VERSION "8"

NS_ :

BS_:

BU_:Matrix

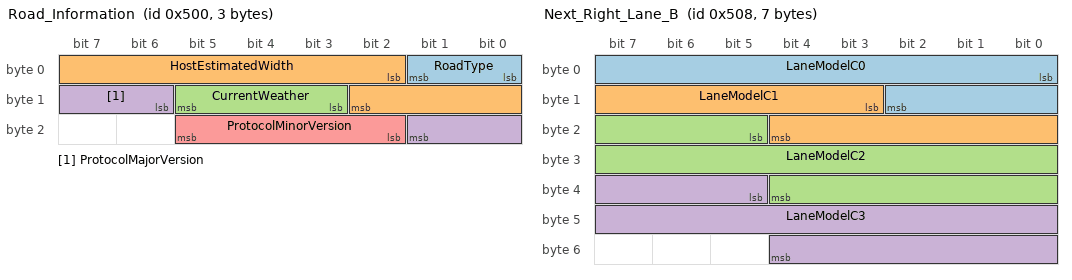
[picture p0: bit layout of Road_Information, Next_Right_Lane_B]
BO_ 1280 Road_Information: 3 Matrix
 SG_ RoadType : 0|2@1+ (1,0) [0|3] "Enum" Matrix
 SG_ HostEstimatedWidth : 2|9@1+ (1,0.01) [0|4] "meter" Matrix
 SG_ CurrentWeather : 11|3@1+ (1,0) [0|7] "Enum" Matrix
 SG_ ProtocolMajorVersion : 14|4@1+ (1,0) [0|15] "NA" Matrix
 SG_ ProtocolMinorVersion : 18|4@1+ (1,0) [0|15] "NA" Matrix

BO_ 1288 Next_Right_Lane_B: 7 Matrix
 SG_ LaneModelC0 : 0|11@1- (0.01,0) [-10|10] "meter" Matrix
 SG_ LaneModelC1 : 11|10@1+ (0.0009765625,-0.357) [-0.357|0.357] "rad" Matrix
 SG_ LaneModelC2 : 21|16@1- (9.77E-007,0) [-0.032|0.032] "1/meter" Matrix
 SG_ LaneModelC3 : 37|16@1- (3.7252902985E-009,0) [-0.000122|0.000122] "1/meter^2" Matrix

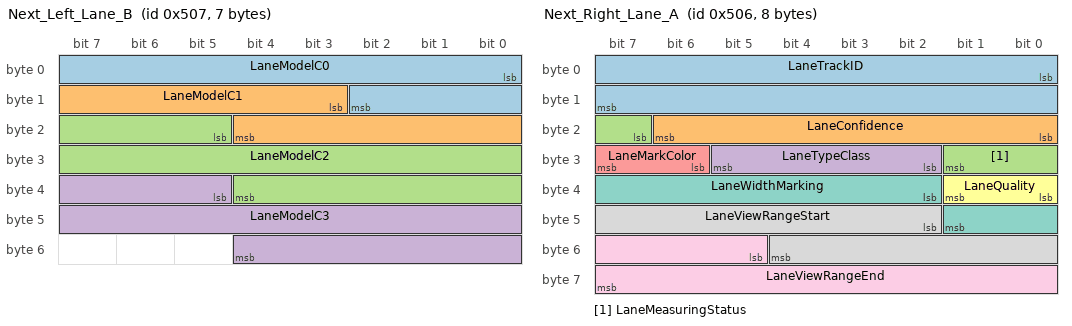
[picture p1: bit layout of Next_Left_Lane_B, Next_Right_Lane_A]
BO_ 1287 Next_Left_Lane_B: 7 Matrix
 SG_ LaneModelC0 : 0|11@1- (0.01,0) [-10|10] "meter" Matrix
 SG_ LaneModelC1 : 11|10@1+ (0.0009765625,-0.357) [-0.357|0.357] "rad" Matrix
 SG_ LaneModelC2 : 21|16@1- (9.77E-007,0) [-0.032|0.032] "1/meter" Matrix
 SG_ LaneModelC3 : 37|16@1- (3.7252902985E-009,0) [-0.000122|0.000122] "1/meter^2" Matrix

BO_ 1286 Next_Right_Lane_A: 8 Matrix
 SG_ LaneTrackID : 0|16@1+ (1,0) [0|65535] "NA" Matrix
 SG_ LaneConfidence : 16|7@1+ (1,0) [0|100] "prob" Matrix
 SG_ LaneMeasuringStatus : 23|3@1+ (1,0) [0|7] "enum" Matrix
 SG_ LaneTypeClass : 26|4@1+ (1,0) [0|15] "Enum" Matrix
 SG_ LaneMarkColor : 30|2@1+ (1,0) [0|3] "Enum" Matrix
 SG_ LaneQuality : 32|2@1+ (1,0) [0|3] "Enum" Matrix
 SG_ LaneWidthMarking : 34|8@1+ (0.01,0) [0|1] "m" Matrix
 SG_ LaneViewRangeStart : 42|11@1+ (0.1,0) [0|200] "meter" Matrix
 SG_ LaneViewRangeEnd : 53|11@1+ (0.1,0) [0|200] "meter" Matrix

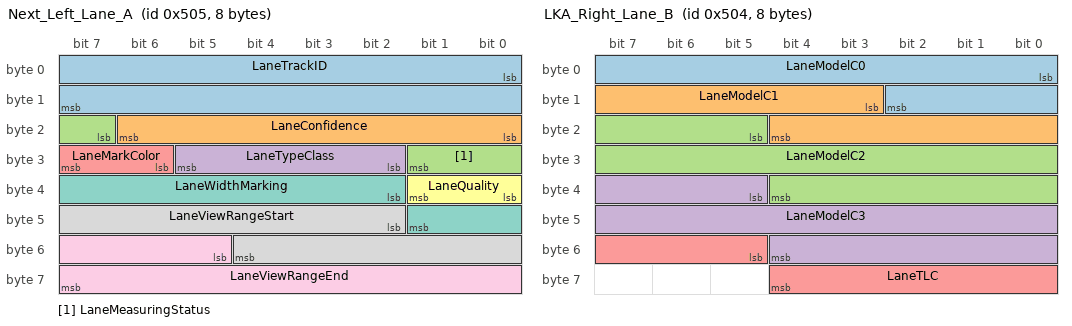
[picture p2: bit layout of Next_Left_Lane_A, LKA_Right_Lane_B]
BO_ 1285 Next_Left_Lane_A: 8 Matrix
 SG_ LaneTrackID : 0|16@1+ (1,0) [0|65535] "NA" Matrix
 SG_ LaneConfidence : 16|7@1+ (1,0) [0|100] "prob" Matrix
 SG_ LaneMeasuringStatus : 23|3@1+ (1,0) [0|7] "enum" Matrix
 SG_ LaneTypeClass : 26|4@1+ (1,0) [0|15] "Enum" Matrix
 SG_ LaneMarkColor : 30|2@1+ (1,0) [0|3] "Enum" Matrix
 SG_ LaneQuality : 32|2@1+ (1,0) [0|3] "Enum" Matrix
 SG_ LaneWidthMarking : 34|8@1+ (0.01,0) [0|1] "m" Matrix
 SG_ LaneViewRangeStart : 42|11@1+ (0.1,0) [0|200] "meter" Matrix
 SG_ LaneViewRangeEnd : 53|11@1+ (0.1,0) [0|200] "meter" Matrix

BO_ 1284 LKA_Right_Lane_B: 8 Matrix
 SG_ LaneModelC0 : 0|11@1- (0.01,0) [-10|10] "meter" Matrix
 SG_ LaneModelC1 : 11|10@1+ (0.0009765625,-0.357) [-0.357|0.357] "rad" Matrix
 SG_ LaneModelC2 : 21|16@1- (9.77E-007,0) [-0.032|0.032] "1/meter" Matrix
 SG_ LaneModelC3 : 37|16@1- (3.7252902985E-009,0) [-0.000122|0.000122] "1/meter^2" Matrix
 SG_ LaneTLC : 53|8@1+ (0.01,0) [0|2] "s" Matrix

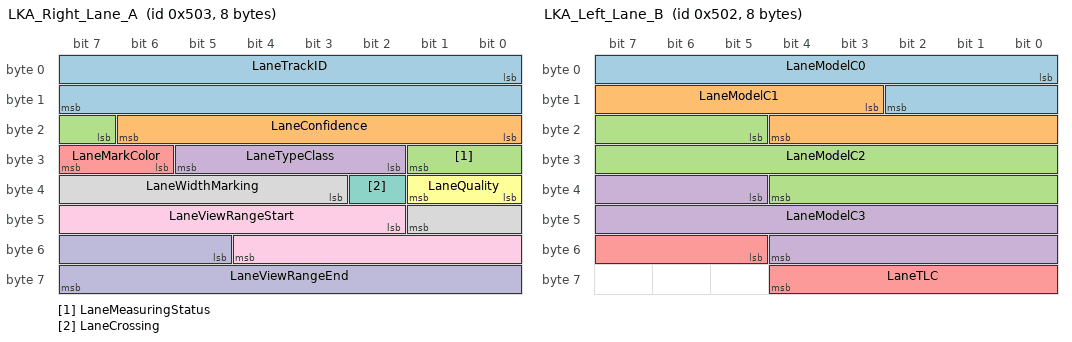
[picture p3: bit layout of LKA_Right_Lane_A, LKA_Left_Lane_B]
BO_ 1283 LKA_Right_Lane_A: 8 Matrix
 SG_ LaneTrackID : 0|16@1+ (1,0) [0|65535] "NA" Matrix
 SG_ LaneConfidence : 16|7@1+ (1,0) [0|100] "prob" Matrix
 SG_ LaneMeasuringStatus : 23|3@1+ (1,0) [0|7] "enum" Matrix
 SG_ LaneTypeClass : 26|4@1+ (1,0) [0|15] "Enum" Matrix
 SG_ LaneMarkColor : 30|2@1+ (1,0) [0|3] "Enum" Matrix
 SG_ LaneQuality : 32|2@1+ (1,0) [0|3] "Enum" Matrix
 SG_ LaneCrossing : 34|1@1+ (1,0) [0|1] "NA" Matrix
 SG_ LaneWidthMarking : 35|7@1+ (0.01,0) [0|1] "m" Matrix
 SG_ LaneViewRangeStart : 42|11@1+ (0.1,0) [0|200] "meter" Matrix
 SG_ LaneViewRangeEnd : 53|11@1+ (0.1,0) [0|200] "meter" Matrix

BO_ 1282 LKA_Left_Lane_B: 8 Matrix
 SG_ LaneModelC0 : 0|11@1- (0.01,0) [-10|10] "meter" Matrix
 SG_ LaneModelC1 : 11|10@1+ (0.0009765625,-0.357) [-0.357|0.357] "rad" Matrix
 SG_ LaneModelC2 : 21|16@1- (9.77E-007,0) [-0.032|0.032] "1/meter" Matrix
 SG_ LaneModelC3 : 37|16@1- (3.7252902985E-009,0) [-0.000122|0.000122] "1/meter^2" Matrix
 SG_ LaneTLC : 53|8@1+ (0.01,0) [0|2] "s" Matrix

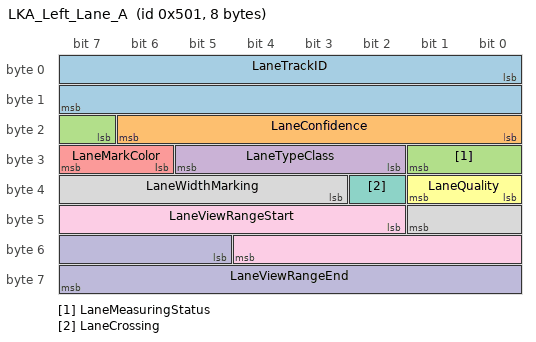
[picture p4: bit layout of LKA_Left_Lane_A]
BO_ 1281 LKA_Left_Lane_A: 8 Matrix
 SG_ LaneTrackID : 0|16@1+ (1,0) [0|65535] "NA" Matrix
 SG_ LaneConfidence : 16|7@1+ (1,0) [0|100] "prob" Matrix
 SG_ LaneMeasuringStatus : 23|3@1+ (1,0) [0|7] "enum" Matrix
 SG_ LaneTypeClass : 26|4@1+ (1,0) [0|15] "Enum" Matrix
 SG_ LaneMarkColor : 30|2@1+ (1,0) [0|3] "Enum" Matrix
 SG_ LaneQuality : 32|2@1+ (1,0) [0|3] "Enum" Matrix
 SG_ LaneCrossing : 34|1@1+ (1,0) [0|1] "NA" Matrix
 SG_ LaneWidthMarking : 35|7@1+ (0.01,0) [0|1] "m" Matrix
 SG_ LaneViewRangeStart : 42|11@1+ (0.1,0) [0|200] "meter" Matrix
 SG_ LaneViewRangeEnd : 53|11@1+ (0.1,0) [0|200] "meter" Matrix

CM_ SG_ 1280 RoadType "RoadType from Scene Model";
CM_ SG_ 1280 HostEstimatedWidth "Multi-frame estimation of host lane width to be used for prediction or another driving cue/ scene cue";
CM_ SG_ 1280 CurrentWeather "Weather from Scene Model";
CM_ SG_ 1280 ProtocolMajorVersion "hb_Lanes: Major Version of Protocol";
CM_ SG_ 1280 ProtocolMinorVersion "hb_Lanes: Minor Version of Protocol";
CM_ SG_ 1288 LaneModelC0 "Ci is coefficient corresponding to variable with power of 'i'";
CM_ SG_ 1288 LaneModelC1 "Ci is coefficient corresponding to variable with power of 'i'";
CM_ SG_ 1288 LaneModelC2 "Ci is coefficient corresponding to variable with power of 'i'";
CM_ SG_ 1288 LaneModelC3 "Ci is coefficient corresponding to variable with power of 'i'";
CM_ SG_ 1287 LaneModelC0 "Ci is coefficient corresponding to variable with power of 'i'";
CM_ SG_ 1287 LaneModelC1 "Ci is coefficient corresponding to variable with power of 'i'";
CM_ SG_ 1287 LaneModelC2 "Ci is coefficient corresponding to variable with power of 'i'";
CM_ SG_ 1287 LaneModelC3 "Ci is coefficient corresponding to variable with power of 'i'";
CM_ SG_ 1286 LaneTrackID "Lane Track ID";
CM_ SG_ 1286 LaneConfidence "Confidence of lane mark";
CM_ SG_ 1286 LaneMeasuringStatus "Were measurements predicted, old, or not valid";
CM_ SG_ 1286 LaneTypeClass "Reserved. Double line ENUM of Lane Mark Type Classification";
CM_ SG_ 1286 LaneMarkColor "ENUM lane mark color";
CM_ SG_ 1286 LaneViewRangeStart "near";
CM_ SG_ 1286 LaneViewRangeEnd "far";
CM_ SG_ 1285 LaneTrackID "Lane Track ID";
CM_ SG_ 1285 LaneConfidence "Confidence of lane mark";
CM_ SG_ 1285 LaneMeasuringStatus "Were measurements predicted, old, or not valid";
CM_ SG_ 1285 LaneTypeClass "Reserved. Double line ENUM of Lane Mark Type Classification";
CM_ SG_ 1285 LaneMarkColor "ENUM lane mark color";
CM_ SG_ 1285 LaneViewRangeStart "near";
CM_ SG_ 1285 LaneViewRangeEnd "far";
CM_ SG_ 1284 LaneModelC0 "Ci is coefficient corresponding to variable with power of 'i'";
CM_ SG_ 1284 LaneModelC1 "Ci is coefficient corresponding to variable with power of 'i'";
CM_ SG_ 1284 LaneModelC2 "Ci is coefficient corresponding to variable with power of 'i'";
CM_ SG_ 1284 LaneModelC3 "Ci is coefficient corresponding to variable with power of 'i'";
CM_ SG_ 1283 LaneTrackID "Lane Track ID";
CM_ SG_ 1283 LaneConfidence "Confidence of lane mark";
CM_ SG_ 1283 LaneMeasuringStatus "Were measurements predicted, old, or not valid";
CM_ SG_ 1283 LaneTypeClass "Reserved. Double line ENUM of Lane Mark Type Classification";
CM_ SG_ 1283 LaneMarkColor "ENUM lane mark color";
CM_ SG_ 1283 LaneViewRangeStart "near";
CM_ SG_ 1283 LaneViewRangeEnd "far";
CM_ SG_ 1282 LaneModelC0 "Ci is coefficient corresponding to variable with power of 'i'";
CM_ SG_ 1282 LaneModelC1 "Ci is coefficient corresponding to variable with power of 'i'";
CM_ SG_ 1282 LaneModelC2 "Ci is coefficient corresponding to variable with power of 'i'";
CM_ SG_ 1282 LaneModelC3 "Ci is coefficient corresponding to variable with power of 'i'";
CM_ SG_ 1281 LaneTrackID "Lane Track ID";
CM_ SG_ 1281 LaneConfidence "Confidence of lane mark";
CM_ SG_ 1281 LaneMeasuringStatus "Were measurements predicted, old, or not valid";
CM_ SG_ 1281 LaneTypeClass "Reserved. Double line ENUM of Lane Mark Type Classification";
CM_ SG_ 1281 LaneMarkColor "ENUM lane mark color";
CM_ SG_ 1281 LaneViewRangeStart "near";
CM_ SG_ 1281 LaneViewRangeEnd "far";
BA_DEF_  "BusType" STRING ;
BA_DEF_DEF_  "BusType" "CAN";
VAL_ 1280 RoadType 3 "Rural" 2 "Urban" 1 "Highway" 0 "Unknown" ;
VAL_ 1280 CurrentWeather 4 "Foggy(Reserved)" 3 "Snow" 2 "Rainy_HeavyRainy" 1 "Sunny_Cloudy" 0 "Unknown" ;
VAL_ 1286 LaneMeasuringStatus 4 "NOT_VALID" 3 "PREDICTED" 2 "MEASURED" 1 "NEW" 0 "UNKNOWN" ;
VAL_ 1286 LaneTypeClass 15 "Invalid" 8 "Barrier" 7 "Double Lane(Double Solid)" 6 "Double Lane(Double Dashed)" 5 "Double Lane(Left Solid, Right Dashed)" 4 "Double Lane(Left Dashed, Right Solid)" 3 "Dashed" 2 "Road Edge" 1 "Solid" 0 "Unknown" ;
VAL_ 1286 LaneMarkColor 3 "Blue_Green" 2 "Yellow_Orange_Red" 1 "White" 0 "Unknown" ;
VAL_ 1286 LaneQuality 3 "Very High quality" 2 "High quality" 1 "Low quality" 0 "Unknown" ;
VAL_ 1285 LaneMeasuringStatus 4 "NOT_VALID" 3 "PREDICTED" 2 "MEASURED" 1 "NEW" 0 "UNKNOWN" ;
VAL_ 1285 LaneTypeClass 15 "Invalid" 8 "Barrier" 7 "Double Lane(Double Solid)" 6 "Double Lane(Double Dashed)" 5 "Double Lane(Left Solid, Right Dashed)" 4 "Double Lane(Left Dashed, Right Solid)" 3 "Dashed" 2 "Road Edge" 1 "Solid" 0 "Unknown" ;
VAL_ 1285 LaneMarkColor 3 "Blue_Green" 2 "Yellow_Orange_Red" 1 "White" 0 "Unknown" ;
VAL_ 1285 LaneQuality 3 "Very High quality" 2 "High quality" 1 "Low quality" 0 "Unknown" ;
VAL_ 1283 LaneMeasuringStatus 4 "NOT_VALID" 3 "PREDICTED" 2 "MEASURED" 1 "NEW" 0 "UNKNOWN" ;
VAL_ 1283 LaneTypeClass 15 "Invalid" 8 "Barrier" 7 "Double Lane(Double Solid)" 6 "Double Lane(Double Dashed)" 5 "Double Lane(Left Solid, Right Dashed)" 4 "Double Lane(Left Dashed, Right Solid)" 3 "Dashed" 2 "Road Edge" 1 "Solid" 0 "Unknown" ;
VAL_ 1283 LaneMarkColor 3 "Blue_Green" 2 "Yellow_Orange_Red" 1 "White" 0 "Unknown" ;
VAL_ 1283 LaneQuality 3 "Very High quality" 2 "High quality" 1 "Low quality" 0 "Unknown" ;
VAL_ 1283 LaneCrossing 1 "TRUE" 0 "FALSE" ;
VAL_ 1281 LaneMeasuringStatus 4 "NOT_VALID" 3 "PREDICTED" 2 "MEASURED" 1 "NEW" 0 "UNKNOWN" ;
VAL_ 1281 LaneTypeClass 15 "Invalid" 8 "Barrier" 7 "Double Lane(Double Solid)" 6 "Double Lane(Double Dashed)" 5 "Double Lane(Left Solid, Right Dashed)" 4 "Double Lane(Left Dashed, Right Solid)" 3 "Dashed" 2 "Road Edge" 1 "Solid" 0 "Unknown" ;
VAL_ 1281 LaneMarkColor 3 "Blue_Green" 2 "Yellow_Orange_Red" 1 "White" 0 "Unknown" ;
VAL_ 1281 LaneQuality 3 "Very High quality" 2 "High quality" 1 "Low quality" 0 "Unknown" ;
VAL_ 1281 LaneCrossing 1 "TRUE" 0 "FALSE" ;
